# max32630 register map
Vendor: Maxim Integrated; Series: max3263x; File version: 1.2
CPU: CM4 r0p1, little endian, no MPU, FPU, 3 interrupt priority bits
Registers are 32-bit, read-write, reset 0x0 unless marked. A register's access mark holds for its fields unless they carry their own. Offsets are from the block's base; [hi:lo] are bit positions; {n}, {i} and the like mark numbered series.

## I2CM0 — I2C Master Interface
Base 0x40016000
Same registers: I2CM1 0x40017000, I2CM2 0x40018000
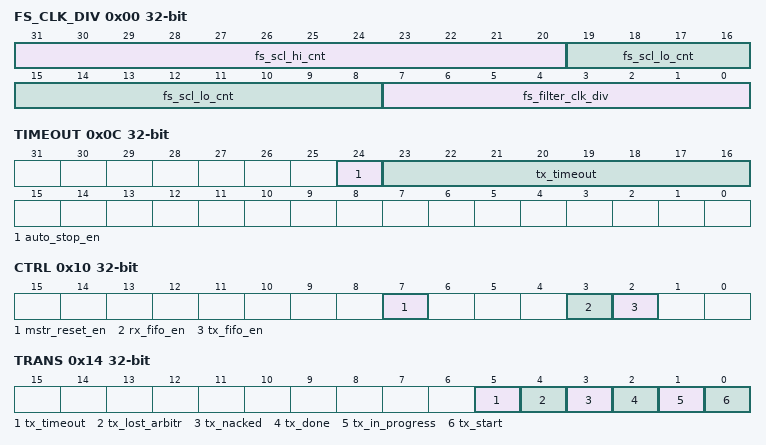
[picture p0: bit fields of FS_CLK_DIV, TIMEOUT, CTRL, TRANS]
0x00 FS_CLK_DIV — I2C Master Full Speed SCL Clock Settings
  [31:20] fs_scl_hi_cnt — Full Speed SCL High Count
  [19:8] fs_scl_lo_cnt — Full Speed SCL Low Count
  [7:0] fs_filter_clk_div — Full Speed Filter Clock Divisor
0x0C TIMEOUT — I2C Master Timeout and Auto-Stop Settings
  [24] auto_stop_en — Auto-Stop Enable
  [23:16] tx_timeout — Transaction Timeout Limit
0x10 CTRL — I2C Master Control Register
  [7] mstr_reset_en — Master Reset
  [3] rx_fifo_en — Master Results FIFO Enable
  [2] tx_fifo_en — Master Transaction FIFO Enable
0x14 TRANS — I2C Master Transaction Start and Status Flags
  [5] tx_timeout ro — Transaction Timed Out
  [4] tx_lost_arbitr ro — Transaction Lost Arbitration
  [3] tx_nacked ro — Transaction Nacked
  [2] tx_done ro — Transaction Done
  [1] tx_in_progress ro — Transaction In Progress
  [0] tx_start — Start Transaction
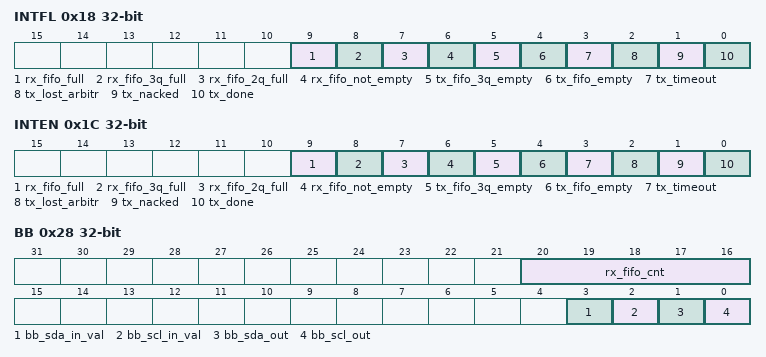
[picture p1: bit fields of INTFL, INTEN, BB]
0x18 INTFL — I2C Master Interrupt Flags
  [9] rx_fifo_full write-1-clears — Results FIFO Full Int Status
  [8] rx_fifo_3q_full write-1-clears — Results FIFO 3Q Full Int Status
  [7] rx_fifo_2q_full write-1-clears — Results FIFO 2Q Full Int Status
  [6] rx_fifo_not_empty write-1-clears — Results FIFO Not Empty Int Status
  [5] tx_fifo_3q_empty write-1-clears — Transaction FIFO 3Q Empty Int Status
  [4] tx_fifo_empty write-1-clears — Transaction FIFO Empty Int Status
  [3] tx_timeout write-1-clears — Transaction Timed Out Int Status
  [2] tx_lost_arbitr write-1-clears — Transaction Lost Arbitration Int Status
  [1] tx_nacked write-1-clears — Transaction NACKed Int Status
  [0] tx_done write-1-clears — Transaction Done Int Status
0x1C INTEN — I2C Master Interrupt Enable/Disable Controls
  [9] rx_fifo_full — Results FIFO Full Int Enable
  [8] rx_fifo_3q_full — Results FIFO 3Q Full Int Enable
  [7] rx_fifo_2q_full — Results FIFO 2Q Full Int Enable
  [6] rx_fifo_not_empty — Results FIFO Not Empty Int Enable
  [5] tx_fifo_3q_empty — Transaction FIFO 3Q Empty Int Enable
  [4] tx_fifo_empty — Transaction FIFO Empty Int Enable
  [3] tx_timeout — Transaction Timed Out Int Enable
  [2] tx_lost_arbitr — Transaction Lost Arbitration IntEnable
  [1] tx_nacked — Transaction NACKed Int Enable
  [0] tx_done — Transaction Done Int Enable
0x28 BB — I2C Master Bit-Bang Control Register
  [20:16] rx_fifo_cnt ro — Results FIFO Data Received Count
  [3] bb_sda_in_val ro — Bit Bang SCL Input Value
  [2] bb_scl_in_val ro — Bit Bang SCL Input Value
  [1] bb_sda_out — Bit Bang SDA Output
  [0] bb_scl_out — Bit Bang SCL Output

## I2CS — I2C Slave Interface (Mailbox type)
Base 0x40019000
0x00 CLK_DIV — I2C Slave Clock Divisor Control
  [7:0] fs_filter_clock_div — FS Filter Clock Divisor
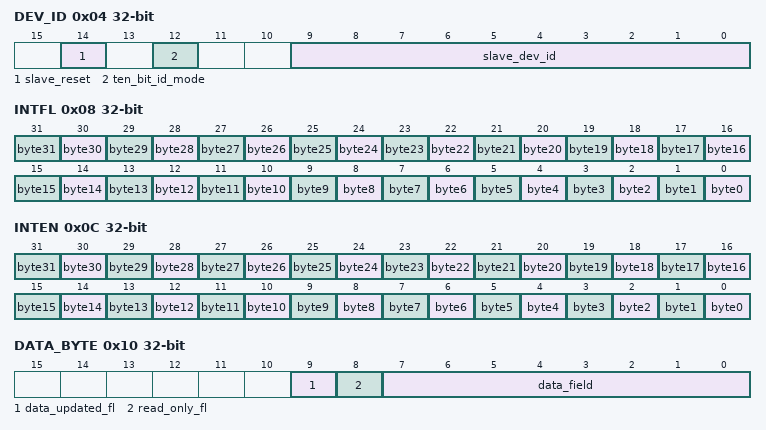
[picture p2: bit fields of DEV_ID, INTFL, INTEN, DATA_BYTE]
0x04 DEV_ID — I2C Slave Device ID Register
  [14] slave_reset
  [12] ten_bit_id_mode — 10-bit ID Mode
  [9:0] slave_dev_id — Slave Device ID
0x08 INTFL — I2CS Interrupt Flags
  [n] byte{n} write-1-clears (n=0..31) — Updated Byte {n}
0x0C INTEN — I2CS Interrupt Enable/Disable Controls
  [n] byte{n} (n=0..31) — Updated Byte {n}
0x10 DATA_BYTE — I2CS Data Byte
  [9] data_updated_fl ro — Byte Updated Flag
  [8] read_only_fl — Read Only Flag
  [7:0] data_field

## SPIM0 — SPI Master Interface
Base 0x4001A000
Same registers: SPIM1 0x4001B000, SPIM2 0x4001C000
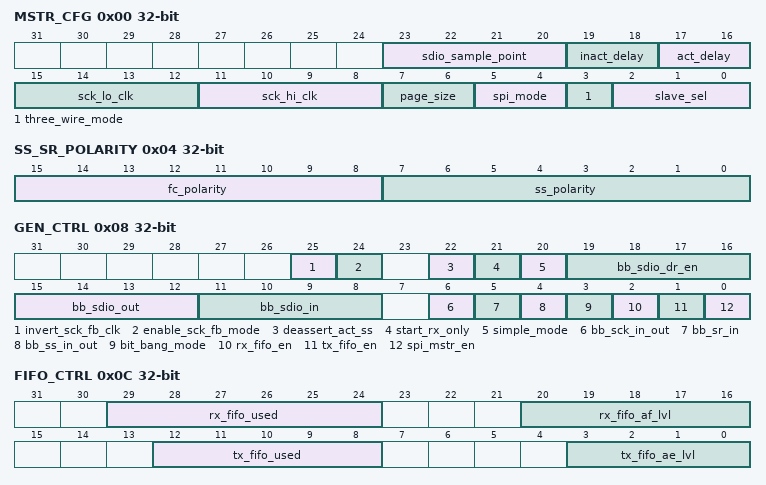
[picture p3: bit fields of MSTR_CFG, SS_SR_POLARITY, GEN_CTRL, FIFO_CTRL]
0x00 MSTR_CFG — SPI Master Configuration Register
  [23:20] sdio_sample_point
  [19:18] inact_delay — SS Inactive Timing
  [17:16] act_delay — SS Active Timing
  [15:12] sck_lo_clk — SCK Low Clocks
  [11:8] sck_hi_clk — SCK High Clocks
  [7:6] page_size
  [5:4] spi_mode
  [3] three_wire_mode — 3-Wire Mode
  [2:0] slave_sel — SPI Slave Select
0x04 SS_SR_POLARITY — SPI Master Polarity Control for SS and SR Signals
  [15:8] fc_polarity — SR Signal Polarity [FC Polarity]
  [7:0] ss_polarity — SS Signal Polarity
0x08 GEN_CTRL — SPI Master General Control Register
  [25] invert_sck_fb_clk — Invert SCK_FB Clock
  [24] enable_sck_fb_mode
  [22] deassert_act_ss — Deassert Currently Selected SS
  [21] start_rx_only — Start Simple RX Only Transaction
  [20] simple_mode — Enable SPI Simple Mode
  [19:16] bb_sdio_dr_en — Bit Bang SDIO Drive Enable
  [15:12] bb_sdio_out — Bit Bang SDIO Output
  [11:8] bb_sdio_in ro — Bit Bang SDIO Input
  [6] bb_sck_in_out — Bit Bang SCK Input/Output
  [5] bb_sr_in ro — Bit Bang SR Input
  [4] bb_ss_in_out — Bit Bang SS Input/Output
  [3] bit_bang_mode — Bit Bang Mode Enable
  [2] rx_fifo_en — Results FIFO Enable
  [1] tx_fifo_en — Transaction FIFO Enable
  [0] spi_mstr_en — Enable/Disable SPI Master
0x0C FIFO_CTRL — SPI Master FIFO Control Register
  [29:24] rx_fifo_used ro — Results FIFO Used
  [20:16] rx_fifo_af_lvl — Results FIFO AF Level
  [12:8] tx_fifo_used ro — Transaction FIFO Used
  [3:0] tx_fifo_ae_lvl — Transaction FIFO AE Level
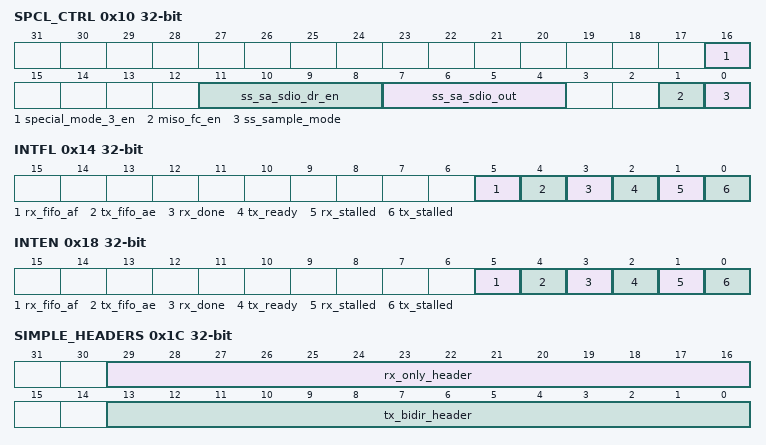
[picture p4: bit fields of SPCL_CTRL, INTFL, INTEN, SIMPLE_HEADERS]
0x10 SPCL_CTRL — SPI Master Special Mode Controls
  [16] special_mode_3_en — Enable Special SPI Mode 3
  [11:8] ss_sa_sdio_dr_en — SDIO Active Drive Mode
  [7:4] ss_sa_sdio_out — SDIO Active Output Value
  [1] miso_fc_en — SDIO(1) to SR(0) Mode
  [0] ss_sample_mode
0x14 INTFL — SPI Master Interrupt Flags
  [5] rx_fifo_af write-1-clears — RXFIFO Almost Full Int Status
  [4] tx_fifo_ae write-1-clears — TXFIFO Almost Empty Int Status
  [3] rx_done write-1-clears — Results Done Int Status
  [2] tx_ready write-1-clears — Transaction Ready Int Status
  [1] rx_stalled write-1-clears — Results Stalled Int Status
  [0] tx_stalled write-1-clears — Transaction Stalled Int Status
0x18 INTEN — SPI Master Interrupt Enable/Disable Settings
  [5] rx_fifo_af — RXFIFO Almost Full Int Enable
  [4] tx_fifo_ae — TXFIFO Almost Empty Int Enable
  [3] rx_done — Results Done Int Enable
  [2] tx_ready — Transaction Ready Int Enable
  [1] rx_stalled — Results Stalled Int Enable
  [0] tx_stalled — Transaction Stalled Int Enable
0x1C SIMPLE_HEADERS — SPI Master Simple Mode Transaction Headers
  [29:16] rx_only_header — RX Only Transaction Header
  [13:0] tx_bidir_header — TX Bidir Transaction Header
